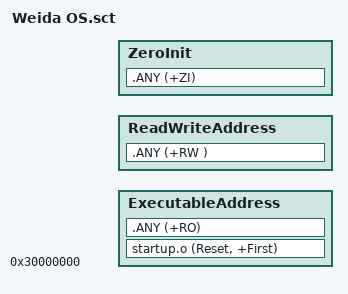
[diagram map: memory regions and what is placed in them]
; *************************************************************
; *** Scatter-Loading Description File generated by uVision ***
; *************************************************************
LoadAddress  0x30000000   ;程序将被加载至此,RO_Base
{   
 
       ExecutableAddress +0  ; load address = execution address
       {
	          startup.o (Reset, +First)    ;所有的*.o的文件，第一段为RESET代码段
             ; *(InRoot$$Sections)
              .ANY (+RO)             ;所有只读段都在这里
        }
  

       ReadWriteAddress  +0;0x30200000	  ;紧跟在ExecutableAddress 的后面
	    {
            .ANY (+RW )
        }

		ZeroInit    +0
		{
		  
		  .ANY  (+ZI)
		 }
}

